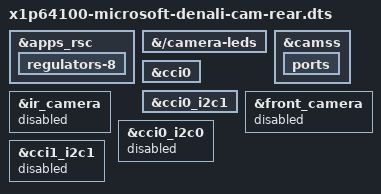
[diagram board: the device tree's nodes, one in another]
// SPDX-License-Identifier: BSD-3-Clause
/*
 * Diagnostic variant: enable the rear OV13858 camera path for a first test boot.
 *
 * Requires camera patches 0001-0021. Only the rear endpoint is in the CAMSS
 * graph; the front and IR endpoints are removed so they cannot block registration.
 * The IR emitter and flash remain undescribed (risk S2).
 *
 * Expected on the device (see hardware/cameras/test-plan.md): ov13858 probes and reads
 * the chip id; /dev/media* shows the CAMSS graph; the indicator LED lights while streaming.
 * Not a patch, not part of the RPM; built with scripts/kernel-dev.sh variant by the kernel worker.
 */
#include "x1p64100-microsoft-denali.dts"

&apps_rsc {
	regulators-8 {
		status = "okay";
	};
};

&{/camera-leds} {
	status = "okay";
};

&camss {
	status = "okay";
};

&cci0 {
	status = "okay";
};

&cci0_i2c1 {
	status = "okay";
};

/* Only the rear sensor participates in this diagnostic graph. */
&camss {
	ports {
		/delete-node/ port@0;
		/delete-node/ port@2;
	};
};

&ir_camera {
	status = "disabled";
	/delete-node/ port;
};

&front_camera {
	status = "disabled";
	/delete-node/ port;
};

&cci0_i2c0 {
	status = "disabled";
};

&cci1_i2c1 {
	status = "disabled";
};
